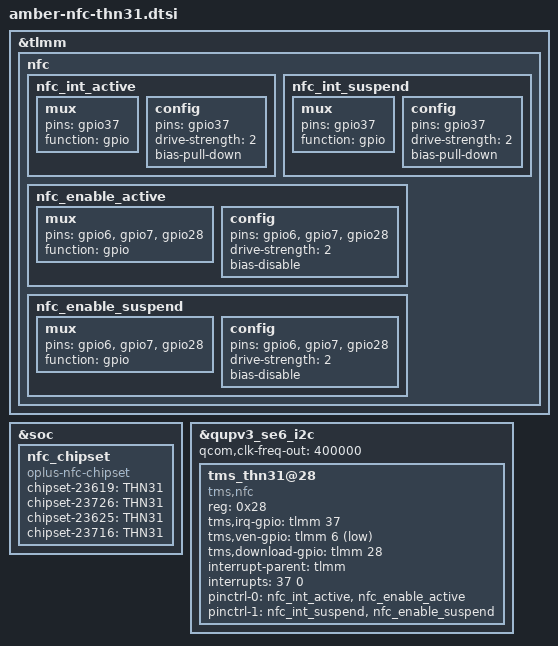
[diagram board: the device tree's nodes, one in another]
/**********************************************************************************
* Copyright (c)  2008-2020  Guangdong oplus Mobile Comm Corp., Ltd
* Description: oplus thn31 nfc dtsi
*
***********************************************************************************/
&tlmm {

    nfc {
        nfc_int_active: nfc_int_active {
            /* active state */
            mux {
                /* NFC Read Interrupt */
                pins = "gpio37";
                function = "gpio";
            };

            config {
                pins = "gpio37";
                drive-strength = <2>; /* 2 MA */
                bias-pull-down;
            };
        };

        nfc_int_suspend: nfc_int_suspend {
            /* sleep state */
            mux {
                /* NFC Read Interrupt */
                pins = "gpio37";
                function = "gpio";
            };

            config {
                pins = "gpio37";
                drive-strength = <2>; /* 2 MA */
                bias-pull-down;
            };
        };

        nfc_enable_active: nfc_enable_active {
            mux {
                /* Enable, Clock request gpios */
                pins = "gpio6", "gpio7", "gpio28";
                function = "gpio";
            };

            config {
                pins = "gpio6", "gpio7", "gpio28";
                drive-strength = <2>; /* 2 MA */
                bias-disable;
            };
        };

        nfc_enable_suspend: nfc_enable_suspend {
            mux {
                pins = "gpio6", "gpio7", "gpio28";
                function = "gpio";
            };

            config {
                pins = "gpio6", "gpio7", "gpio28";
                drive-strength = <2>; /* 2 MA */
                bias-disable;
            };
        };
    };
};

&soc {
    //add for nfc_chipset
    nfc_chipset {
        compatible = "oplus-nfc-chipset";
        chipset-23619 = "THN31";//amber 6450 china
        chipset-23726 = "THN31";//amber 6450 global
        chipset-23625 = "THN31";//amber 7435 china
        chipset-23716 = "THN31";//amber 7435 global
    };
};

&qupv3_se6_i2c {
    status = "ok";
    qcom,clk-freq-out = <400000>;
    tms_thn31@28 {
        compatible = "tms,nfc";
        reg = <0x28>;
        tms,irq-gpio = <&tlmm 37 0x00>;
        tms,ven-gpio = <&tlmm 6 0x01>;
        tms,download-gpio = <&tlmm 28 0x00>;
        //qcom,nq-clkreq = <&tlmm 7 0x00>;
        interrupt-parent = <&tlmm>;
        interrupts = <37 0>;
        interrupt-names = "nfc_irq";
        pinctrl-names = "nfc_active", "nfc_suspend";
        pinctrl-0 = <&nfc_int_active &nfc_enable_active>;
        pinctrl-1 = <&nfc_int_suspend &nfc_enable_suspend>;
    };
};
